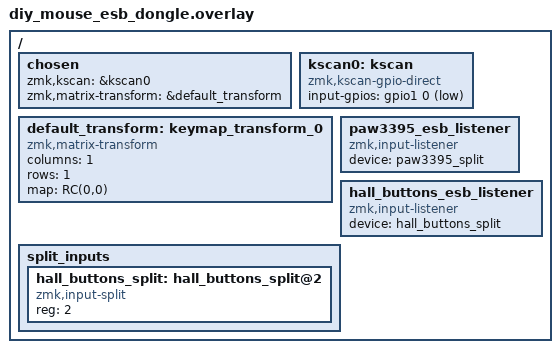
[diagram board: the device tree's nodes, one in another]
#include <dt-bindings/zmk/matrix_transform.h>
#include <dt-bindings/gpio/gpio.h>

/ {
    chosen {
        zmk,kscan = &kscan0;
        zmk,matrix-transform = &default_transform;
    };

    kscan0: kscan {
        compatible = "zmk,kscan-gpio-direct";
        input-gpios = <&gpio1 0 (GPIO_ACTIVE_LOW | GPIO_PULL_UP)>; /* D6 / P1.00 unused */
    };

    default_transform: keymap_transform_0 {
        compatible = "zmk,matrix-transform";
        columns = <1>;
        rows = <1>;
        map = <RC(0,0)>;
    };

    paw3395_esb_listener {
        compatible = "zmk,input-listener";
        device = <&paw3395_split>;
    };

    hall_buttons_esb_listener {
        compatible = "zmk,input-listener";
        device = <&hall_buttons_split>;
    };

    split_inputs {
        hall_buttons_split: hall_buttons_split@2 {
            compatible = "zmk,input-split";
            reg = <2>;
        };
    };
};

#include "diy_mouse_esb_addr.dtsi"
#include "diy_mouse_esb_split.dtsi"
